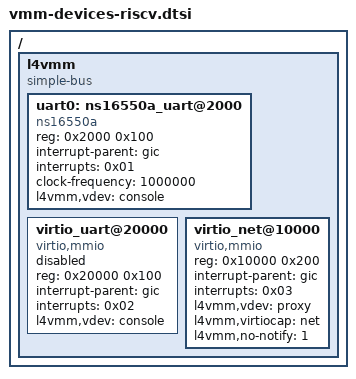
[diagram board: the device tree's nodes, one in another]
/**
 * Basic set of VMM virtual devices for RISC-V guests.
 *
 *  * console device
 *  * network virtio proxy device
 */

/ {
    l4vmm {
        #address-cells = <1>;
        #size-cells = <1>;
        compatible = "simple-bus";
        ranges = <0x0 0x30000000 0x21000>;

        uart0: ns16550a_uart@2000 {
            compatible = "ns16550a";
            reg = <0x2000 0x100>;
            interrupt-parent = <&gic>;
            interrupts = <0x01>;
            clock-frequency = <1000000>;
            l4vmm,vdev = "console";
            /* Redirecting to another vcon channel is possible: */
            /* l4vmm,vcon_cap = "uart"; */
        };

        virtio_uart@20000 {
            compatible = "virtio,mmio";
            reg = <0x20000 0x100>;
            interrupt-parent = <&gic>;
            interrupts = <0x02>;
            l4vmm,vdev = "console";
            /* Emulated UART is used by default for best bring-up experience */
            status = "disabled";
        };

        virtio_net@10000 {
            compatible = "virtio,mmio";
            reg = <0x10000 0x200>;
            interrupt-parent = <&gic>;
            interrupts = <0x03>;
            l4vmm,vdev = "proxy";
            l4vmm,virtiocap = "net";
            l4vmm,no-notify = <1>;
        };
    };
};
